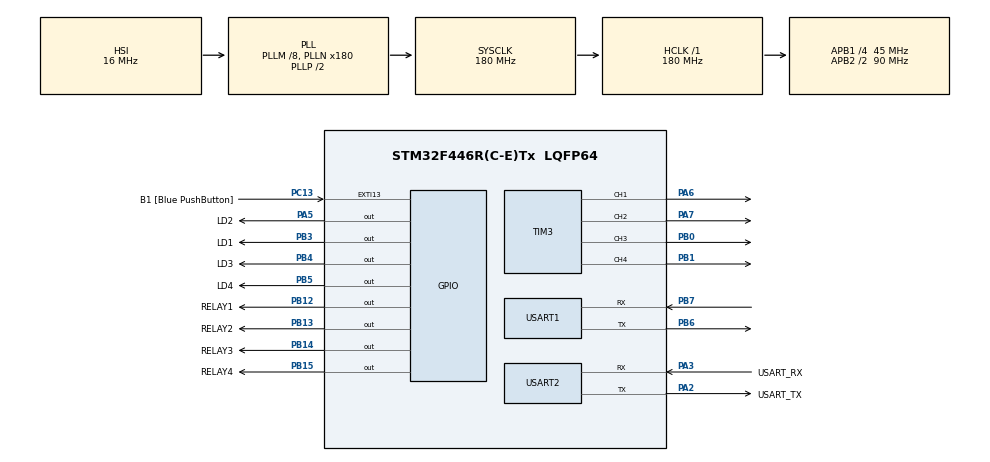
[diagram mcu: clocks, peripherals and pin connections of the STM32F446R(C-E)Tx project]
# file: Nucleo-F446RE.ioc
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Mcu.Family=STM32F4
PH0-OSC_IN.Signal=RCC_OSC_IN
RCC.CortexFreq_Value=180000000
Dma.USART1_TX.3.MemInc=DMA_MINC_ENABLE
Dma.USART1_TX.3.MemDataAlignment=DMA_MDATAALIGN_BYTE
Dma.USART2_TX.1.MemInc=DMA_MINC_ENABLE
PB14.GPIO_Label=RELAY3
PA14.GPIO_Label=TCK
Dma.USART1_RX.2.Instance=DMA2_Stream2
Dma.USART1_TX.3.Direction=DMA_MEMORY_TO_PERIPH
PC13.GPIO_Label=B1 [Blue PushButton]
PB13.GPIO_Label=RELAY2
PB13.Signal=GPIO_Output
PB15.Signal=GPIO_Output
TIM3.Channel-PWM\ Generation4\ CH4=TIM_CHANNEL_4
RCC.SYSCLKSource=RCC_SYSCLKSOURCE_PLLCLK
ProjectManager.StackSize=0x400
Dma.USART1_TX.3.FIFOMode=DMA_FIFOMODE_DISABLE
Dma.USART2_RX.0.Priority=DMA_PRIORITY_LOW
Dma.USART2_RX.0.PeriphDataAlignment=DMA_PDATAALIGN_BYTE
RCC.HCLKFreq_Value=180000000
RCC.APB2TimFreq_Value=180000000
PB6.Signal=USART1_TX
Dma.USART2_TX.1.Mode=DMA_NORMAL
Dma.USART1_TX.3.Mode=DMA_NORMAL
PB6.Mode=Asynchronous
RCC.AHBFreq_Value=180000000
PH0-OSC_IN.Mode=HSE-External-Oscillator
TIM3.Channel-PWM\ Generation1\ CH1=TIM_CHANNEL_1
RCC.HSE_VALUE=8000000
NVIC.TIM8_TRG_COM_TIM14_IRQn=true\:0\:0\:false\:false\:true\:false\:true
PB12.GPIO_Label=RELAY1
Dma.USART2_RX.0.MemDataAlignment=DMA_MDATAALIGN_BYTE
PC14-OSC32_IN.Mode=LSE-External-Oscillator
PA14.Mode=Serial_Wire
Dma.USART2_TX.1.Instance=DMA1_Stream6
Dma.USART1_TX.3.PeriphInc=DMA_PINC_DISABLE
Dma.USART2_RX.0.Instance=DMA1_Stream5
PB7.Signal=USART1_RX
SH.S_TIM3_CH1.0=TIM3_CH1,PWM Generation1 CH1
VP_SYS_VS_tim14.Mode=TIM14
Dma.USART1_TX.3.Instance=DMA2_Stream7
RCC.FLatency-AdvancedSettings=FLASH_LATENCY_5
PH1-OSC_OUT.Mode=HSE-External-Oscillator
Mcu.Package=LQFP64
PB1.Signal=S_TIM3_CH4
PA6.Signal=S_TIM3_CH1
NVIC.DMA2_Stream7_IRQn=true\:5\:0\:true\:false\:true\:false\:true
NVIC.TimeBase=TIM8_TRG_COM_TIM14_IRQn
Dma.USART2_RX.0.PeriphInc=DMA_PINC_DISABLE
USART2.VirtualMode=VM_ASYNC
Dma.USART2_RX.0.FIFOMode=DMA_FIFOMODE_DISABLE
PA2.GPIO_Label=USART_TX
NVIC.TimeBaseIP=TIM14
RCC.APB2CLKDivider=RCC_HCLK_DIV2
PB5.GPIO_Label=LD4
NVIC.DMA2_Stream2_IRQn=true\:5\:0\:true\:false\:true\:false\:true
Dma.Request2=USART1_RX
Dma.Request1=USART2_TX
RCC.APB1TimFreq_Value=90000000
Dma.Request3=USART1_TX
NVIC.USART1_IRQn=true\:5\:0\:true\:false\:true\:true\:true
Dma.Request0=USART2_RX
NVIC.DMA1_Stream6_IRQn=true\:5\:0\:true\:false\:true\:false\:true
Dma.USART1_RX.2.MemDataAlignment=DMA_MDATAALIGN_BYTE
PB4.Signal=GPIO_Output
PA3.Signal=USART2_RX
PB3.GPIO_Label=LD1
PC15-OSC32_OUT.Mode=LSE-External-Oscillator
Dma.USART2_TX.1.Priority=DMA_PRIORITY_LOW
Dma.USART2_TX.1.FIFOMode=DMA_FIFOMODE_DISABLE
PC13.Signal=GPXTI13
Dma.USART2_RX.0.Direction=DMA_PERIPH_TO_MEMORY
RCC.APB1CLKDivider=RCC_HCLK_DIV4
PC14-OSC32_IN.Signal=RCC_OSC32_IN
SH.S_TIM3_CH3.0=TIM3_CH3,PWM Generation3 CH3
Dma.USART2_TX.1.PeriphDataAlignment=DMA_PDATAALIGN_BYTE
Dma.USART1_RX.2.PeriphInc=DMA_PINC_DISABLE
NVIC.USART2_IRQn=true\:5\:0\:true\:false\:true\:true\:true
Dma.USART2_RX.0.Mode=DMA_NORMAL
PA3.Mode=Asynchronous
PA13.Signal=SYS_JTMS-SWDIO
TIM3.Channel-PWM\ Generation3\ CH3=TIM_CHANNEL_3
ProjectManager.TargetToolchain=SW4STM32
NVIC.DMA1_Stream5_IRQn=true\:5\:0\:true\:false\:true\:false\:true
Dma.USART1_RX.2.Mode=DMA_NORMAL
Dma.USART1_RX.2.PeriphDataAlignment=DMA_PDATAALIGN_BYTE
Dma.USART1_TX.3.PeriphDataAlignment=DMA_PDATAALIGN_BYTE
RCC.USBFreq_Value=180000000
PC15-OSC32_OUT.Signal=RCC_OSC32_OUT
PB14.Signal=GPIO_Output
PA5.Signal=GPIO_Output
SH.S_TIM3_CH2.0=TIM3_CH2,PWM Generation2 CH2
Dma.USART2_TX.1.PeriphInc=DMA_PINC_DISABLE
board=NUCLEO-F446RE
Dma.USART1_RX.2.FIFOMode=DMA_FIFOMODE_DISABLE
RCC.VCOOutputFreq_Value=360000000
Dma.USART1_RX.2.Priority=DMA_PRIORITY_LOW
Dma.USART2_TX.1.Direction=DMA_MEMORY_TO_PERIPH
VP_TIM13_VS_ClockSourceINT.Mode=Enable_Timer
RCC.APB2Freq_Value=90000000
Dma.USART1_RX.2.Direction=DMA_PERIPH_TO_MEMORY
PB4.GPIO_Label=LD3
PB15.GPIO_Label=RELAY4
PH1-OSC_OUT.Signal=RCC_OSC_OUT
PA13.Mode=Serial_Wire
Mcu.Name=STM32F446R(C-E)Tx
Dma.USART2_RX.0.MemInc=DMA_MINC_ENABLE
Dma.USART1_RX.2.MemInc=DMA_MINC_ENABLE
PA2.Signal=USART2_TX
PA13.GPIO_Label=TMS
Dma.USART1_TX.3.Priority=DMA_PRIORITY_LOW
RCC.48MHZClocksFreq_Value=84000000
PB3.Signal=GPIO_Output
RCC.SYSCLKFreq_VALUE=180000000
PB5.Signal=GPIO_Output
PA5.GPIO_Label=LD2
PC13.GPIO_ModeDefaultEXTI=GPIO_MODE_IT_FALLING
USART1.VirtualMode=VM_ASYNC
PB7.Mode=Asynchronous
PA14.Signal=SYS_JTCK-SWCLK
ProjectManager.HeapSize=0x200
RCC.HSI_VALUE=16000000
NVIC.TIM8_UP_TIM13_IRQn=true\:0\:0\:false\:false\:true\:true\:true
NVIC.PriorityGroup=NVIC_PRIORITYGROUP_4
TIM3.Channel-PWM\ Generation2\ CH2=TIM_CHANNEL_2
RCC.PLLM=8
RCC.PLLN=180
PA2.Mode=Asynchronous
Dma.USART2_TX.1.MemDataAlignment=DMA_MDATAALIGN_BYTE
RCC.APB1Freq_Value=45000000
VP_CRC_VS_CRC.Mode=CRC_Activate
PB0.Signal=S_TIM3_CH3
PB12.Signal=GPIO_Output
PA3.GPIO_Label=USART_RX
SH.S_TIM3_CH4.0=TIM3_CH4,PWM Generation4 CH4
PA7.Signal=S_TIM3_CH2

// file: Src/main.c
/* USER CODE BEGIN Header */
/**
  ******************************************************************************
  * @file           : main.c
  * @brief          : Main program body
  ******************************************************************************
  * @attention
  *
  * <h2><center>&copy; Copyright (c) 2020 STMicroelectronics.
  * All rights reserved.</center></h2>
  *
  * This software component is licensed by ST under BSD 3-Clause license,
  * the "License"; You may not use this file except in compliance with the
  * License. You may obtain a copy of the License at:
  *                        opensource.org/licenses/BSD-3-Clause
  *
  ******************************************************************************
  */
/* USER CODE END Header */

#include "main.h"
#include "crc.h"
#include "dma.h"
#include "tim.h"
#include "usart.h"
#include "gpio.h"

/* USER CODE BEGIN Includes */
#include "SS_init.h"
#include "SS_platform.h"

/* USER CODE END Includes */

void SystemClock_Config(void);

int main(void)
{

  /* MCU Configuration--------------------------------------------------------*/

  /* Reset of all peripherals, Initializes the Flash interface and the Systick. */
  HAL_Init();

  /* Configure the system clock */
  SystemClock_Config();

  /* Initialize all configured peripherals */
  MX_GPIO_Init();
  MX_DMA_Init();
  MX_TIM13_Init();
  MX_USART2_UART_Init();
  MX_TIM3_Init();
  MX_CRC_Init();
  MX_USART1_UART_Init();
  /* USER CODE BEGIN 2 */
  SS_platform_init();
  SS_init();

  /* USER CODE END 2 */

  /* Infinite loop */
  while (1)
  {

  }
}

void SystemClock_Config(void)
{
  RCC_OscInitTypeDef RCC_OscInitStruct = {0};
  RCC_ClkInitTypeDef RCC_ClkInitStruct = {0};

  /** Configure the main internal regulator output voltage
  */
  __HAL_RCC_PWR_CLK_ENABLE();
  __HAL_PWR_VOLTAGESCALING_CONFIG(PWR_REGULATOR_VOLTAGE_SCALE1);
  /** Initializes the CPU, AHB and APB busses clocks
  */
  RCC_OscInitStruct.OscillatorType = RCC_OSCILLATORTYPE_HSI;
  RCC_OscInitStruct.HSIState = RCC_HSI_ON;
  RCC_OscInitStruct.HSICalibrationValue = RCC_HSICALIBRATION_DEFAULT;
  RCC_OscInitStruct.PLL.PLLState = RCC_PLL_ON;
  RCC_OscInitStruct.PLL.PLLSource = RCC_PLLSOURCE_HSI;
  RCC_OscInitStruct.PLL.PLLM = 8;
  RCC_OscInitStruct.PLL.PLLN = 180;
  RCC_OscInitStruct.PLL.PLLP = RCC_PLLP_DIV2;
  RCC_OscInitStruct.PLL.PLLQ = 2;
  RCC_OscInitStruct.PLL.PLLR = 2;
  if (HAL_RCC_OscConfig(&RCC_OscInitStruct) != HAL_OK)
  {
    Error_Handler();
  }
  /** Activate the Over-Drive mode
  */
  if (HAL_PWREx_EnableOverDrive() != HAL_OK)
  {
    Error_Handler();
  }
  /** Initializes the CPU, AHB and APB busses clocks
  */
  RCC_ClkInitStruct.ClockType = RCC_CLOCKTYPE_HCLK|RCC_CLOCKTYPE_SYSCLK
                              |RCC_CLOCKTYPE_PCLK1|RCC_CLOCKTYPE_PCLK2;
  RCC_ClkInitStruct.SYSCLKSource = RCC_SYSCLKSOURCE_PLLCLK;
  RCC_ClkInitStruct.AHBCLKDivider = RCC_SYSCLK_DIV1;
  RCC_ClkInitStruct.APB1CLKDivider = RCC_HCLK_DIV4;
  RCC_ClkInitStruct.APB2CLKDivider = RCC_HCLK_DIV2;

  if (HAL_RCC_ClockConfig(&RCC_ClkInitStruct, FLASH_LATENCY_5) != HAL_OK)
  {
    Error_Handler();
  }
}

 /**
  * @brief  Period elapsed callback in non blocking mode
  * @note   This function is called  when TIM14 interrupt took place, inside
  * HAL_TIM_IRQHandler(). It makes a direct call to HAL_IncTick() to increment
  * a global variable "uwTick" used as application time base.
  * @param  htim : TIM handle
  * @retval None
  */
void HAL_TIM_PeriodElapsedCallback(TIM_HandleTypeDef *htim)
{
  if (htim->Instance == TIM14) {
    HAL_IncTick();
  }
}

void Error_Handler(void)
{
}

/************************ (C) COPYRIGHT STMicroelectronics *****END OF FILE****/
